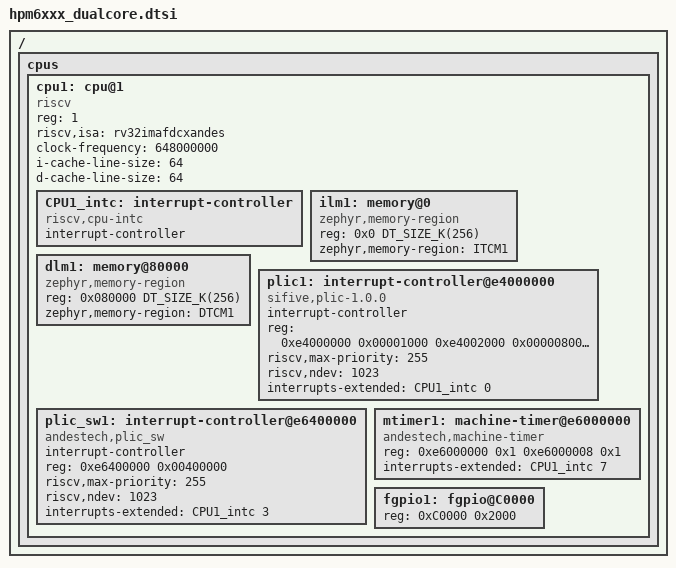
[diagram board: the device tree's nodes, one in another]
/*
 * Copyright 2024 hpmicro
 * SPDX-License-Identifier: Apache-2.0
 */

/ {
	cpus {
		cpu1: cpu@1 {
			compatible = "riscv"; /* riscv custom */
			reg = <1>;
			status = "okay";
			riscv,isa = "rv32imafdcxandes";
			clock-frequency = <648000000>;
			i-cache-line-size = <64>;
			d-cache-line-size = <64>;

			CPU1_intc: interrupt-controller {
				#interrupt-cells = <1>;
				interrupt-controller;
				compatible = "riscv,cpu-intc";
			};

			#address-cells = <1>;
			#size-cells = <1>;
			ilm1: memory@0 {
				compatible = "zephyr,memory-region";
				reg = <0x0 DT_SIZE_K(256)>;
				zephyr,memory-region = "ITCM1";
			};

			dlm1: memory@80000 {
				compatible = "zephyr,memory-region";
				reg = <0x080000 DT_SIZE_K(256)>;
				zephyr,memory-region = "DTCM1";
			};

			plic1: interrupt-controller@e4000000 {
				compatible = "sifive,plic-1.0.0";
				#address-cells = <1>;
				#interrupt-cells = <2>;
				interrupt-controller;
				reg = <	0xe4000000 0x00001000
					0xe4002000 0x00000800
					0xe4200000 0x00010000 >;
				reg-names = "prio", "irq_en", "reg";
				riscv,max-priority = <255>;
				riscv,ndev = <1023>;
				interrupts-extended = <&CPU1_intc 0>;
			};

			plic_sw1: interrupt-controller@e6400000 {
				compatible = "andestech,plic_sw";
				#address-cells = <1>;
				#interrupt-cells = <2>;
				interrupt-controller;
				reg = <0xe6400000 0x00400000>;
				riscv,max-priority = <255>;
				riscv,ndev = <1023>;
				interrupts-extended = <&CPU1_intc 3>;
			};

			mtimer1: machine-timer@e6000000 {
				compatible = "andestech,machine-timer";
				reg = <0xe6000000 0x1
				0xe6000008 0x1>;
				interrupts-extended = <&CPU1_intc 7>;
			};

			fgpio1: fgpio@C0000 {
				reg = <0xC0000 0x2000>;
			};
		};
	};
};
